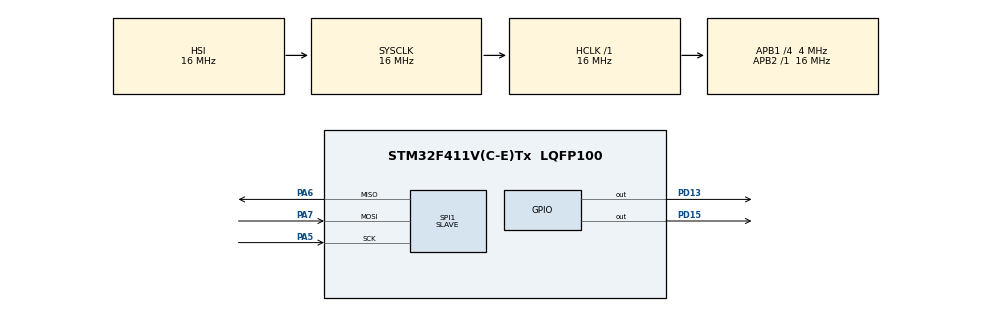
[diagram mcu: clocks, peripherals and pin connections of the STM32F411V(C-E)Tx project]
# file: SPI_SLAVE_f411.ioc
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Mcu.Family=STM32F4
Mcu.Name=STM32F411V(C-E)Tx
Mcu.Package=LQFP100
NVIC.PriorityGroup=NVIC_PRIORITYGROUP_0
PA5.Mode=Full_Duplex_Slave
PA5.Signal=SPI1_SCK
PA6.Mode=Full_Duplex_Slave
PA6.Signal=SPI1_MISO
PA7.Mode=Full_Duplex_Slave
PA7.Signal=SPI1_MOSI
PD13.Signal=GPIO_Output
PD15.Signal=GPIO_Output
ProjectManager.HeapSize=0x200
ProjectManager.StackSize=0x400
ProjectManager.TargetToolchain=STM32CubeIDE
RCC.48MHZClocksFreq_Value=96000000
RCC.AHBFreq_Value=16000000
RCC.APB1CLKDivider=RCC_HCLK_DIV4
RCC.APB1Freq_Value=4000000
RCC.APB1TimFreq_Value=8000000
RCC.APB2Freq_Value=16000000
RCC.APB2TimFreq_Value=16000000
RCC.CortexFreq_Value=16000000
RCC.HCLKFreq_Value=16000000
RCC.HSE_VALUE=8000000
RCC.HSI_VALUE=16000000
RCC.LSE_VALUE=32768
RCC.PLLI2SM=5
RCC.PLLI2SN=200
RCC.PLLM=4
RCC.PLLP=RCC_PLLP_DIV4
RCC.PLLQ=8
RCC.SYSCLKFreq_VALUE=16000000
RCC.VCOOutputFreq_Value=768000000
SPI1.Direction=SPI_DIRECTION_2LINES
SPI1.Mode=SPI_MODE_SLAVE
SPI1.VirtualType=VM_SLAVE
board=STM32F411E-DISCO

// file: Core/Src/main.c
/* USER CODE BEGIN Header */
/**
  ******************************************************************************
  * @file           : main.c
  * @brief          : Main program body
  ******************************************************************************
  * @attention
  *
  * Copyright (c) 2024 STMicroelectronics.
  * All rights reserved.
  *
  * This software is licensed under terms that can be found in the LICENSE file
  * in the root directory of this software component.
  * If no LICENSE file comes with this software, it is provided AS-IS.
  *
  ******************************************************************************
  */
/* USER CODE END Header */
#include "main.h"

SPI_HandleTypeDef hspi1;

void SystemClock_Config(void);
static void MX_GPIO_Init(void);
static void MX_SPI1_Init(void);

int main(void)
{

  /* MCU Configuration--------------------------------------------------------*/

  /* Reset of all peripherals, Initializes the Flash interface and the Systick. */
  HAL_Init();

  /* Configure the system clock */
  SystemClock_Config();

  /* Initialize all configured peripherals */
  MX_GPIO_Init();
  MX_SPI1_Init();
  /* USER CODE BEGIN 2 */
  uint8_t received_data = 0;
  /* USER CODE END 2 */

  /* Infinite loop */
  /* USER CODE BEGIN WHILE */
  while (1)
  {
	  if (HAL_SPI_Receive(&hspi1, &received_data, 1, HAL_MAX_DELAY) == HAL_OK) {
	             if (received_data == 0x01) { // Check received command
	                 HAL_GPIO_TogglePin(GPIOD, GPIO_PIN_15); // Turn on LED
//	                 char message[] = "LED ON Command Received!\r\n";
//	                 HAL_UART_Transmit(&huart2, (uint8_t *)message, strlen(message), HAL_MAX_DELAY);
	             }

	         }
//	  else
//	  	             {
//	  	            	 HAL_GPIO_WritePin(GPIOD, GPIO_PIN_13, GPIO_PIN_SET);
//	  	             }
    /* USER CODE END WHILE */

  }
}

void SystemClock_Config(void)
{
  RCC_OscInitTypeDef RCC_OscInitStruct = {0};
  RCC_ClkInitTypeDef RCC_ClkInitStruct = {0};

  /** Configure the main internal regulator output voltage
  */
  __HAL_RCC_PWR_CLK_ENABLE();
  __HAL_PWR_VOLTAGESCALING_CONFIG(PWR_REGULATOR_VOLTAGE_SCALE1);

  /** Initializes the RCC Oscillators according to the specified parameters
  * in the RCC_OscInitTypeDef structure.
  */
  RCC_OscInitStruct.OscillatorType = RCC_OSCILLATORTYPE_HSI;
  RCC_OscInitStruct.HSIState = RCC_HSI_ON;
  RCC_OscInitStruct.HSICalibrationValue = RCC_HSICALIBRATION_DEFAULT;
  RCC_OscInitStruct.PLL.PLLState = RCC_PLL_NONE;
  if (HAL_RCC_OscConfig(&RCC_OscInitStruct) != HAL_OK)
  {
    Error_Handler();
  }

  /** Initializes the CPU, AHB and APB buses clocks
  */
  RCC_ClkInitStruct.ClockType = RCC_CLOCKTYPE_HCLK|RCC_CLOCKTYPE_SYSCLK
                              |RCC_CLOCKTYPE_PCLK1|RCC_CLOCKTYPE_PCLK2;
  RCC_ClkInitStruct.SYSCLKSource = RCC_SYSCLKSOURCE_HSI;
  RCC_ClkInitStruct.AHBCLKDivider = RCC_SYSCLK_DIV1;
  RCC_ClkInitStruct.APB1CLKDivider = RCC_HCLK_DIV4;
  RCC_ClkInitStruct.APB2CLKDivider = RCC_HCLK_DIV1;

  if (HAL_RCC_ClockConfig(&RCC_ClkInitStruct, FLASH_LATENCY_0) != HAL_OK)
  {
    Error_Handler();
  }
}

static void MX_SPI1_Init(void)
{

  /* SPI1 parameter configuration*/
  hspi1.Instance = SPI1;
  hspi1.Init.Mode = SPI_MODE_SLAVE;
  hspi1.Init.Direction = SPI_DIRECTION_2LINES;
  hspi1.Init.DataSize = SPI_DATASIZE_8BIT;
  hspi1.Init.CLKPolarity = SPI_POLARITY_LOW;
  hspi1.Init.CLKPhase = SPI_PHASE_1EDGE;
  hspi1.Init.NSS = SPI_NSS_SOFT;
  hspi1.Init.FirstBit = SPI_FIRSTBIT_MSB;
  hspi1.Init.TIMode = SPI_TIMODE_DISABLE;
  hspi1.Init.CRCCalculation = SPI_CRCCALCULATION_DISABLE;
  hspi1.Init.CRCPolynomial = 10;
  if (HAL_SPI_Init(&hspi1) != HAL_OK)
  {
    Error_Handler();
  }

}

static void MX_GPIO_Init(void)
{
  GPIO_InitTypeDef GPIO_InitStruct = {0};

  /* GPIO Ports Clock Enable */
  __HAL_RCC_GPIOA_CLK_ENABLE();
  __HAL_RCC_GPIOD_CLK_ENABLE();

  /*Configure GPIO pin Output Level */
  HAL_GPIO_WritePin(GPIOD, GPIO_PIN_13|GPIO_PIN_15, GPIO_PIN_RESET);

  /*Configure GPIO pins : PD13 PD15 */
  GPIO_InitStruct.Pin = GPIO_PIN_13|GPIO_PIN_15;
  GPIO_InitStruct.Mode = GPIO_MODE_OUTPUT_PP;
  GPIO_InitStruct.Pull = GPIO_NOPULL;
  GPIO_InitStruct.Speed = GPIO_SPEED_FREQ_LOW;
  HAL_GPIO_Init(GPIOD, &GPIO_InitStruct);

}

void Error_Handler(void)
{
  __disable_irq();
  while (1)
  {
  }
}
